# MSS_RCM_MSS_RCM register map
Vendor: Texas Instruments
Peripheral module from a debugger description file (folder AM263).
Registers are 8-bit, read-write, reset 0x0 unless marked. A register's access mark holds for its fields unless they carry their own. Offsets are as the file gives them; lines under a group give offsets from that group; [hi:lo] are bit positions; {n}, {i} and the like mark numbered series; 'fields as' and 'values as' point back to an identical list; <NAME> marks a mode.

## MSS_RCM_MSS_RCM
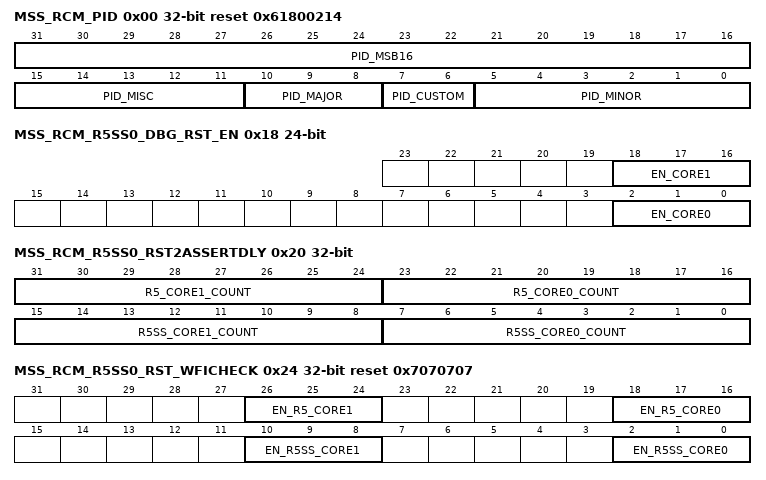
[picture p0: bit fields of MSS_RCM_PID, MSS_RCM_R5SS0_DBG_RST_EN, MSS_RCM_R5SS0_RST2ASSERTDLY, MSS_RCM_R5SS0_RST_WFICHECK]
0x00 MSS_RCM_PID 32-bit ro reset 0x61800214
  [31:16] PID_MSB16 — Not Defined
  [15:11] PID_MISC — Not Defined
  [10:8] PID_MAJOR — Not Defined
  [7:6] PID_CUSTOM — Not Defined
  [5:0] PID_MINOR — Not Defined
0x10 MSS_RCM_R5SS0_RST_STATUS 16-bit ro reset 0x3
  [10:0] CAUSE — Has the status because of which reset has happened. Bit0: POR ResetBit1: Warm Reset (ALso set during POR Reset)Bit2: CR5SS0 STC ResetBit3 Reset for CORE0 and MSS_CORE00_VIM using MSS_RCM::MSS_CR5SSA0_RST_CTRLBit4: Reset for CORE1 and MSS_CORE10_VIM using MSS_RCM::MSS_CR5SSB0_RST_CTRLBit5: Reset for CORE0 only using MSS_RCM::MSS_CORE00_RST_CTRLBit6: Reset for CORE1 only using using MSS_RCM::MSS_CORE10_RST_CTRLBit7: Reset for CORE0 and MSS_CORE00_VIM caused because of reset request by debugger in CORE00 Bit8: Reset for CORE10 and MSS_CORE10_VIM caused because of reset request by debugger in CORE10Bit9: Reset for CR5SS0 by the RESET FSM using MSS_CTRL::R5SS0_CONTROL_RESET_FSM_TRIGGER Bit 10 : MSS_RCM.MSS_CR5SS_POR_RST_CTRL0
0x14 MSS_RCM_R5SS0_RST_CAUSE_CLR
  [2:0] CLR — Write pulse bit field:Clear bit for rst cause register (writing '111' will clear the rst cause register)
0x18 MSS_RCM_R5SS0_DBG_RST_EN 24-bit
  [18:16] EN_CORE1 — writing '111' will block debug reset request from CORE1 toggling reset for CORE1 of respective R5SS
  [2:0] EN_CORE0 — writing '111' will block debug reset request from CORE0 toggling reset for CORE0 of respective R5SS
0x1C MSS_RCM_R5SS0_RST_ASSERDLY reset 0xF
  [7:0] COUNT — Value decides number of cycles reset should be kept asserted for CR5SS related resets. Programming a value of 0xFF will keep the reset asserted untill a new value other than 0xFF is written to this registerThe actual duration is count + 2 cycles. S/W Recommended value for this is 0x0FThe COUNT is applicable to both CPU cores
0x20 MSS_RCM_R5SS0_RST2ASSERTDLY 32-bit
  [31:24] R5_CORE1_COUNT — Value decides number of cycles to wait before asserting reset for local reset for CORE1
  [23:16] R5_CORE0_COUNT — Value decides number of cycles to wait before asserting reset for local reset for CORE0.
  [15:8] R5SS_CORE1_COUNT — Value decides number of cycles to wait before asserting reset for global reset for CORE1
  [7:0] R5SS_CORE0_COUNT — Value decides number of cycles to wait before asserting reset for global reset for CORE0.
0x24 MSS_RCM_R5SS0_RST_WFICHECK 32-bit reset 0x7070707
  [26:24] EN_R5_CORE1 — writing '000' will disable check for WFI before local reset assertion of CORE0
  [18:16] EN_R5_CORE0 — writing '000' will disable check for WFI before local reset assertion of CORE0
  [10:8] EN_R5SS_CORE1 — writing '000' will disable check for WFI before global reset assertion of CORE1
  [2:0] EN_R5SS_CORE0 — writing '000' will disable check for WFI before global reset assertion of CORE0
0x30 MSS_RCM_R5SS1_RST_STATUS 16-bit ro reset 0x3
  [10:0] CAUSE — Has the status because of which reset has happened. Bit0: POR ResetBit1: Warm Reset (ALso set during POR Reset)Bit2: CR5SS1 STC ResetBit3 Reset for CORE0 and MSS_CORE00_VIM using MSS_RCM::MSS_CR5SSA0_RST_CTRLBit4: Reset for CORE1 and MSS_CORE10_VIM using MSS_RCM::MSS_CR5SSB0_RST_CTRLBit5: Reset for CORE0 only using MSS_RCM::MSS_CORE00_RST_CTRLBit6: Reset for CORE1 only using using MSS_RCM::MSS_CORE10_RST_CTRLBit7: Reset for CORE0 and MSS_CORE00_VIM caused because of reset request by debugger in CORE00 Bit8: Reset for CORE10 and MSS_CORE10_VIM caused because of reset request by debugger in CORE10Bit9: Reset for CR5SS0 by the RESET FSM using MSS_CTRL::R5SS0_CONTROL_RESET_FSM_TRIGGER Bit 10 : MSS_RCM.MSS_CR5SS_POR_RST_CTRL0
0x34 MSS_RCM_R5SS1_RST_CAUSE_CLR
  fields as MSS_RCM_R5SS0_RST_CAUSE_CLR
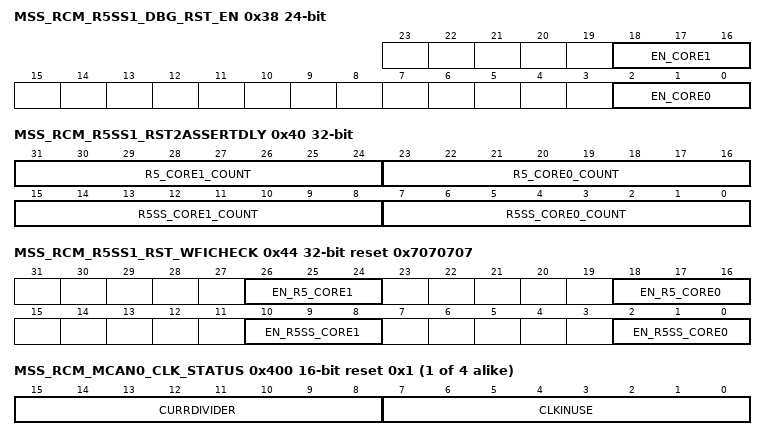
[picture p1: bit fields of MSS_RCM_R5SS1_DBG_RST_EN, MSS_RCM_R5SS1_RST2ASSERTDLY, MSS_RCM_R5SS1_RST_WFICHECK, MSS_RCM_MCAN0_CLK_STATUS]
0x38 MSS_RCM_R5SS1_DBG_RST_EN 24-bit
  fields as MSS_RCM_R5SS0_DBG_RST_EN
0x3C MSS_RCM_R5SS1_RST_ASSERDLY reset 0xF
  fields as MSS_RCM_R5SS0_RST_ASSERDLY
0x40 MSS_RCM_R5SS1_RST2ASSERTDLY 32-bit
  fields as MSS_RCM_R5SS0_RST2ASSERTDLY
0x44 MSS_RCM_R5SS1_RST_WFICHECK 32-bit reset 0x7070707
  fields as MSS_RCM_R5SS0_RST_WFICHECK
{0x100+4i} MSS_RCM_MCAN{i}_CLK_SRC_SEL 16-bit (i=0..3)
  [11:0] CLKSRCSEL — Select line for selecting source clock for corresponding MCAN.Data should be loaded as multibit. For example: if '0x5' should be selected then '0x555' should be configured to the register.Refer to AM602 clock spec for source clock reference
0x110 MSS_RCM_QSPI0_CLK_SRC_SEL 16-bit
  [11:0] CLKSRCSEL — Select line for selecting source clock for QSPI.Data should be loaded as multibit. For example: if '0x5' should be selected then '0x555' should be configured to the register.Refer to AM602 clock spec for source clock reference
{0x114+4i} MSS_RCM_RTI{i}_CLK_SRC_SEL 16-bit (i=0..3)
  [11:0] CLKSRCSEL — Select line for selecting source clock for Corresponding RTI.Data should be loaded as multibit. For example: if '0x5' should be selected then '0x555' should be configured to the register.Refer to AM602 clock spec for source clock reference
{0x128+4i} MSS_RCM_WDT{i}_CLK_SRC_SEL 16-bit (i=0..3)
  [11:0] CLKSRCSEL — Select line for selecting source clock for WDT.Data should be loaded as multibit. For example: if '0x5' should be selected then '0x555' should be configured to the register.Refer to AM602 clock spec for source clock reference
{0x13C+4i} MSS_RCM_MCSPI{i}_CLK_SRC_SEL 16-bit (i=0..4)
  [11:0] CLKSRCSEL — Select line for selecting source clock for Corresponding SPI.Data should be loaded as multibit. For example: if '0x5' should be selected then '0x555' should be configured to the register.Refer to AM602 clock spec for source clock reference
0x150 MSS_RCM_MMC0_CLK_SRC_SEL 16-bit
  [11:0] CLKSRCSEL — Select line for selecting source clock for MMCSD.Data should be loaded as multibit. For example: if '0x5' should be selected then '0x555' should be configured to the register.Refer to AM602 clock spec for source clock reference
0x154 MSS_RCM_ICSSM0_UART0_CLK_SRC_SEL 16-bit
  [11:0] CLKSRCSEL — Select line for selecting source clock for ICSSM_UCLK.Data should be loaded as multibit. For example: if '0x5' should be selected then '0x555' should be configured to the register.Refer to AM602 clock spec for source clock reference
0x158 MSS_RCM_CPTS_CLK_SRC_SEL 16-bit
  [11:0] CLKSRCSEL — Select line for selecting source clock for CPTS.Data should be loaded as multibit. For example: if '0x5' should be selected then '0x555' should be configured to the register.Refer to AM602 clock spec for source clock reference
0x15C MSS_RCM_GPMC_CLK_SRC_SEL 16-bit
  [11:0] GPMC_CLK_SRC_SEL — Select line for selecting source clock for GPMC. Data should be loaded as multibit. For example: if '0x5' should be selected then '0x555' should be configured to the register.Refer to AM602 clock spec for source clock reference
0x160 MSS_RCM_CONTROLSS_PLL_CLK_SRC_SEL 16-bit
  [11:0] CLKSRCSEL — Select line for selecting source clock for CONTROLSS_PLL.Data should be loaded as multibit. For example: if '0x5' should be selected then '0x555' should be configured to the register.Refer to AM602 clock spec for source clock reference
0x164 MSS_RCM_I2C_CLK_SRC_SEL 16-bit
  [11:0] CLKSRCSEL — Select line for selecting source clock for I2C.Data should be loaded as multibit. For example: if '0x5' should be selected then '0x555' should be configured to the register.Refer to AM602 clock spec for source clock reference
{0x174+4i} MSS_RCM_LIN{i}_UART{i}_CLK_SRC_SEL 16-bit (i=0..5)
  [11:0] CLKSRCSEL — Select line for selecting source clock for corresponding UART and LIN.Data should be loaded as multibit. For example: if '0x5' should be selected then '0x555' should be configured to the register.Refer to AM602 clock spec for source clock reference
{0x200+4i} MSS_RCM_MCAN{i}_CLK_DIV_VAL 16-bit (i=0..3)
  [11:0] CLKDIVR — Divider value corresponding MCAN selected clock.Data should be loaded as multibit. For example: if divider value of 8(1000) should be selected then '100010001000' should be configured to the register.Refer to AM602 clock planner for clock reference
0x210 MSS_RCM_QSPI0_CLK_DIV_VAL 16-bit
  [11:0] CLKDIVR — Divider value QSPI selected clock.Data should be loaded as multibit. For example: if divider value of '0x8' should be selected then '0x888' should be configured to the register.Refer to AM602 clock spec for clock reference
{0x214+4i} MSS_RCM_RTI{i}_CLK_DIV_VAL 16-bit (i=0..3)
  [11:0] CLKDIVR — Divider value Corresponding RTI selected clock.Data should be loaded as multibit. For example: if divider value of '0x8' should be selected then '0x888' should be configured to the register.Refer to AM602 clock spec for clock reference
{0x228+4i} MSS_RCM_WDT{i}_CLK_DIV_VAL 16-bit (i=0..3)
  [11:0] CLKDIVR — Divider value WDT selected clock.Data should be loaded as multibit. For example: if divider value of '0x8' should be selected then '0x888' should be configured to the register.Refer to AM602 clock spec for clock reference
{0x23C+4i} MSS_RCM_MCSPI{i}_CLK_DIV_VAL 16-bit (i=0..4)
  [11:0] CLKDIVR — Divider value Corresponding SPI selected clock.Data should be loaded as multibit. For example: if divider value of '0x8' should be selected then '0x888' should be configured to the register.Refer to AM602 clock spec for clock reference
0x250 MSS_RCM_MMC0_CLK_DIV_VAL 16-bit
  [11:0] CLKDIVR — Divider value MMCSD selected clock.Data should be loaded as multibit. For example: if divider value of '0x8' should be selected then '0x888' should be configured to the register.Refer to AM602 clock spec for clock reference
0x254 MSS_RCM_ICSSM0_UART_CLK_DIV_VAL 16-bit
  [11:0] CLKDIVR — Divider value ICSSM_UCLK selected clock.Data should be loaded as multibit. For example: if divider value of '0x8' should be selected then '0x888' should be configured to the register.Refer to AM602 clock spec for clock reference
0x258 MSS_RCM_CPTS_CLK_DIV_VAL 16-bit
  [11:0] CLKDIVR — Divider value CPTS selected clock.Data should be loaded as multibit. For example: if divider value of '0x8' should be selected then '0x888' should be configured to the register.Refer to AM602 clock spec for clock reference
0x25C MSS_RCM_GPMC_CLK_DIV_VAL 16-bit
  [11:0] CLKDIVR — Divider value GPMC selected clock.Data should be loaded as multibit. For example: if divider value of '0x8' should be selected then '0x888' should be configured to the register.Refer to AM602 clock spec for clock reference
0x260 MSS_RCM_CONTROLSS_PLL_CLK_DIV_VAL 16-bit
  [11:0] CLKDIVR — Divider value CONTROLSS_PLL selected clock.Data should be loaded as multibit. For example: if divider value of '0x8' should be selected then '0x888' should be configured to the register.Refer to AM602 clock spec for clock reference
0x264 MSS_RCM_I2C_CLK_DIV_VAL 16-bit
  [11:0] CLKDIVR — Divider value I2C selected clock.Data should be loaded as multibit. For example: if divider value of '0x8' should be selected then '0x888' should be configured to the register.Refer to AM602 clock spec for clock reference
{0x274+4i} MSS_RCM_LIN{i}_UART{i}_CLK_DIV_VAL 16-bit (i=0..5)
  [11:0] CLKDIVR — Divider value for corresponding UART and LIN selected clock.Data should be loaded as multibit. For example: if divider value of '0x8' should be selected then '0x888' should be configured to the register.Refer to AM602 clock spec for clock reference
0x28C MSS_RCM_RGMII_250_CLK_DIV_VAL 16-bit reset 0x111
  [11:0] CLKDIVR — Divider value RGMII selected clock.Data should be loaded as multibit. For example: if divider value of '0x8' should be selected then '0x888' should be configured to the register.Refer to AM602 clock spec for clock reference
0x290 MSS_RCM_RGMII_50_CLK_DIV_VAL 16-bit reset 0x999
  [11:0] CLKDIVR — Divider value MII100 selected clock.Data should be loaded as multibit. For example: if divider value of '0x8' should be selected then '0x888' should be configured to the register.Refer to AM602 clock spec for clock reference
0x294 MSS_RCM_RGMII_5_CLK_DIV_VAL 24-bit reset 0x636363
  [23:0] CLKDIVR — Divider value MII10 selected clock.Data should be loaded as multibit. For example: if divider value of '0x8' should be selected then '0x888' should be configured to the register.Refer to AM602 clock spec for clock reference
0x298 MSS_RCM_XTAL_MMC_32K_CLK_DIV_VAL 32-bit reset 0x30CC330C
  [29:0] CLKDIVR — Divider value for XTAL_32K clock.Data should be loaded as multibit. For example: if divider value of '0x30C' is required then '0x30CC330C' should be configured to the register.Refer to AM602 clock spec for clock reference
0x29C MSS_RCM_XTAL_TEMPSENSE_32K_CLK_DIV_VAL 32-bit reset 0x30CC330C
  fields as MSS_RCM_XTAL_MMC_32K_CLK_DIV_VAL
0x2A0 MSS_RCM_MSS_ELM_CLK_DIV_VAL 16-bit reset 0x333
  [11:0] CLKDIVR — Divider value ELM clock.Data should be loaded as multibit. For example: if divider value of '0x8' should be selected then '0x888' should be configured to the register.Refer to AM602 clock spec for clock reference
{0x300+4i} MSS_RCM_MCAN{i}_CLK_GATE (i=0..3)
  [2:0] GATED — writing '111' will gate clock for corresponding MCAN
0x310 MSS_RCM_QSPI0_CLK_GATE
  [2:0] GATED — writing '111' will gate clock for QSPI
{0x314+4i} MSS_RCM_RTI{i}_CLK_GATE (i=0..3)
  [2:0] GATED — writing '111' will gate clock for Corresponding RTI
{0x328+4i} MSS_RCM_WDT{i}_CLK_GATE (i=0..3)
  [2:0] GATED — writing '111' will gate clock for WDT
{0x33C+4i} MSS_RCM_MCSPI{i}_CLK_GATE (i=0..4)
  [2:0] GATED — writing '111' will gate clock for Corresponding SPI
0x350 MSS_RCM_MMC0_CLK_GATE
  [2:0] GATED — writing '111' will gate clock for MMCSD
0x354 MSS_RCM_ICSSM0_UART_CLK_GATE
  [2:0] GATED — writing '111' will gate clock for ICSSM_UCLK
0x358 MSS_RCM_CPTS_CLK_GATE
  [2:0] GATED — writing '111' will gate clock for CPTS
0x35C MSS_RCM_GPMC_CLK_GATE
  [2:0] GATED — writing '111' will gate clock for GPMC
0x360 MSS_RCM_CONTROLSS_PLL_CLK_GATE
  [2:0] GATED — writing '111' will gate clock for CONTROLSS_PLL
{0x364+4i} MSS_RCM_I2C{i}_CLK_GATE (i=0..3)
  [2:0] GATED — writing '111' will gate clock for I2C
{0x374+4i} MSS_RCM_LIN{i}_CLK_GATE (i=0..4)
  [2:0] GATED — writing '111' will gate clock for SPIB
{0x38C+4i} MSS_RCM_UART{i}_CLK_GATE (i=0..5)
  [2:0] GATED — writing '111' will gate clock for corresponding UART
0x3A4 MSS_RCM_RGMII_250_CLK_GATE
  [2:0] GATED — writing '111' will gate clock for RGMII
0x3A8 MSS_RCM_RGMII_50_CLK_GATE
  [2:0] GATED — writing '111' will gate clock for MII100
0x3AC MSS_RCM_RGMII_5_CLK_GATE
  [2:0] GATED — writing '111' will gate clock for MII10
0x3B0 MSS_RCM_MMC0_32K_CLK_GATE
  [2:0] GATED — writing '111' will gate clock for MMCSD_32K
0x3B4 MSS_RCM_TEMPSENSE_32K_CLK_GATE
  [2:0] GATED — writing '111' will gate clock for TEMPSENSE_32K
0x3B8 MSS_RCM_CPSW_CLK_GATE
  [2:0] GATED — writing '111' will gate clock for CPSW CPPI
0x3BC MSS_RCM_ICSSM0_IEP_CLK_GATE
  [2:0] GATED — writing '111' will gate clock for ICSSM_IEP
0x3C0 MSS_RCM_ICSSM0_CORE_CLK_GATE
  [2:0] GATED — writing '111' will gate clock for ICSSM_CORE
0x3C4 MSS_RCM_MSS_ICSSM_SYS_CLK_GATE
  [2:0] GATED — writing '111' will gate clock for ICSSM_SYS
0x3C8 MSS_RCM_MSS_ELM_CLK_GATE
  [2:0] GATED — writing '111' will gate clock for ELM
0x3CC MSS_RCM_R5SS0_CORE0_GATE
  [2:0] CLKGATE — writing '111' will gate clock to CORE0 related peripherals inside Cortexr5ss
0x3D0 MSS_RCM_R5SS1_CORE0_GATE
  fields as MSS_RCM_R5SS0_CORE0_GATE
0x3D4 MSS_RCM_R5SS0_CORE1_GATE
  [2:0] CLKGATE — writing '111' will gate clock to CORE1 related peripherals inside Cortexr5ss
0x3D8 MSS_RCM_R5SS1_CORE1_GATE
  fields as MSS_RCM_R5SS0_CORE1_GATE
{0x400+4i} MSS_RCM_MCAN{i}_CLK_STATUS 16-bit ro reset 0x1 (i=0..3)
  [15:8] CURRDIVIDER — Status shows the current divider value choosen for corresponding MCAN
  [7:0] CLKINUSE — Status shows the source clock slected for corresponding MCAN
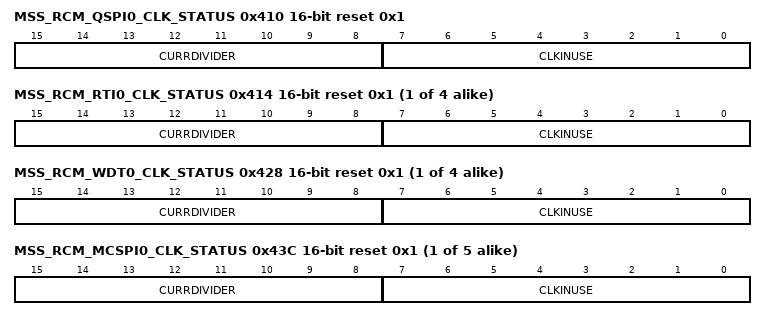
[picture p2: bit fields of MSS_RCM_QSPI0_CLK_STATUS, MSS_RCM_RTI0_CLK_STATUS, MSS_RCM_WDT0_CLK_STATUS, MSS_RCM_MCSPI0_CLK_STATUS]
0x410 MSS_RCM_QSPI0_CLK_STATUS 16-bit ro reset 0x1
  [15:8] CURRDIVIDER — Status shows the current divider value choosen for QSPI
  [7:0] CLKINUSE — Status shows the source clock slected for QSPI
{0x414+4i} MSS_RCM_RTI{i}_CLK_STATUS 16-bit ro reset 0x1 (i=0..3)
  [15:8] CURRDIVIDER — Status shows the current divider value choosen for Corresponding RTI
  [7:0] CLKINUSE — Status shows the source clock slected for Corresponding RTI
{0x428+4i} MSS_RCM_WDT{i}_CLK_STATUS 16-bit ro reset 0x1 (i=0..3)
  [15:8] CURRDIVIDER — Status shows the current divider value choosen for WDT
  [7:0] CLKINUSE — Status shows the source clock slected for WDT
{0x43C+4i} MSS_RCM_MCSPI{i}_CLK_STATUS 16-bit ro reset 0x1 (i=0..4)
  [15:8] CURRDIVIDER — Status shows the current divider value choosen for Corresponding SPI
  [7:0] CLKINUSE — Status shows the source clock slected for Corresponding SPI
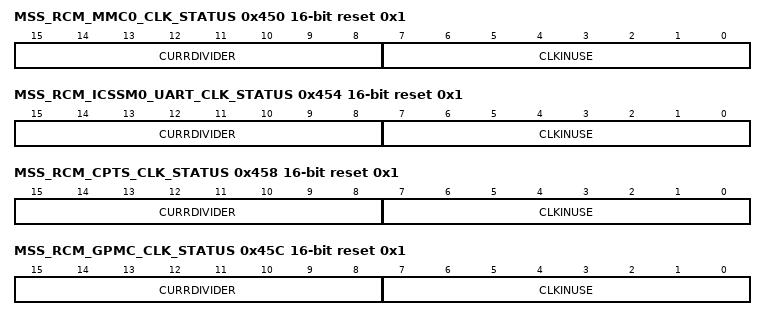
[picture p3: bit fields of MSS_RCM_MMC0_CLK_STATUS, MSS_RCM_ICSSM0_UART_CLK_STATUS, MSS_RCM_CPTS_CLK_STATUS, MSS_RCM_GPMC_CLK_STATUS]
0x450 MSS_RCM_MMC0_CLK_STATUS 16-bit ro reset 0x1
  [15:8] CURRDIVIDER — Status shows the current divider value choosen for MMCSD
  [7:0] CLKINUSE — Status shows the source clock slected for MMCSD
0x454 MSS_RCM_ICSSM0_UART_CLK_STATUS 16-bit ro reset 0x1
  [15:8] CURRDIVIDER — Status shows the current divider value choosen for ICSSM_UCLK
  [7:0] CLKINUSE — Status shows the source clock slected for ICSSM_UCLK
0x458 MSS_RCM_CPTS_CLK_STATUS 16-bit ro reset 0x1
  [15:8] CURRDIVIDER — Status shows the current divider value choosen for CPTS
  [7:0] CLKINUSE — Status shows the source clock slected for CPTS
0x45C MSS_RCM_GPMC_CLK_STATUS 16-bit ro reset 0x1
  [15:8] CURRDIVIDER — Status shows the current divider value choosen for GPMC
  [7:0] CLKINUSE — Status shows the source clock slected for GPMC
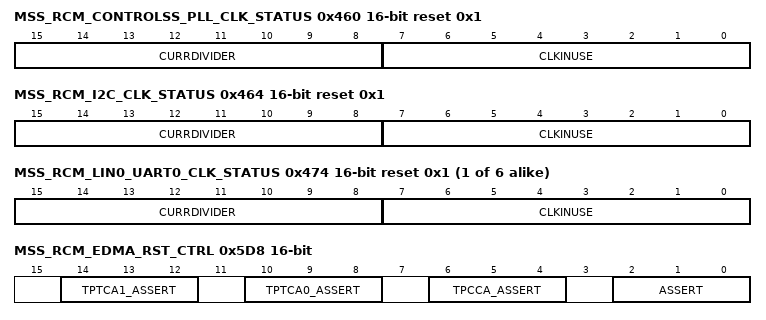
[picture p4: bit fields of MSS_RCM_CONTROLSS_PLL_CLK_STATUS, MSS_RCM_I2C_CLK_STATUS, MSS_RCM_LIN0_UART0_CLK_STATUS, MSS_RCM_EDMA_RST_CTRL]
0x460 MSS_RCM_CONTROLSS_PLL_CLK_STATUS 16-bit ro reset 0x1
  [15:8] CURRDIVIDER — Status shows the current divider value choosen for CONTROLSS_PLL
  [7:0] CLKINUSE — Status shows the source clock slected for CONTROLSS_PLL
0x464 MSS_RCM_I2C_CLK_STATUS 16-bit ro reset 0x1
  [15:8] CURRDIVIDER — Status shows the current divider value choosen for I2C
  [7:0] CLKINUSE — Status shows the source clock slected for I2C
{0x474+4i} MSS_RCM_LIN{i}_UART{i}_CLK_STATUS 16-bit ro reset 0x1 (i=0..5)
  [15:8] CURRDIVIDER — Status shows the current divider value choosen for corresponding UART and LIN
  [7:0] CLKINUSE — Status shows the source clock slected for corresponding UART and LIN
0x48C MSS_RCM_RGMII_250_CLK_STATUS 16-bit ro reset 0x100
  [15:8] CURRDIVIDER — Status shows the current divider value choosen for RGMII
0x490 MSS_RCM_RGMII_50_CLK_STATUS 16-bit ro reset 0x900
  [15:8] CURRDIVIDER — Status shows the current divider value choosen for MII100
0x494 MSS_RCM_RGMII_5_CLK_STATUS 16-bit ro reset 0x6300
  [15:8] CURRDIVIDER — Status shows the current divider value choosen for MII10
0x49C MSS_RCM_MMC0_32K_CLK_STATUS 24-bit ro reset 0x30C00
  [17:8] CURRDIVIDER — Status shows the current divider value choosen for XTAL_32K
0x4A0 MSS_RCM_TEMPSENSE_32K_CLK_STATUS 24-bit ro reset 0x30C00
  fields as MSS_RCM_MMC0_32K_CLK_STATUS
0x4A4 MSS_RCM_MSS_ELM_CLK_STATUS 16-bit ro reset 0x300
  [15:8] CURRDIVIDER — Status shows the current divider value choosen for ELM
0x500 MSS_RCM_R5SS0_POR_RST_CTRL
  [2:0] ASSERT — This feature is for debug purpose only. Software needs to ensure the state of the Device/IP before configuring.write pulse bit field:writing '111' will assert por reset to R5SS Read is always 000
0x504 MSS_RCM_R5SS1_POR_RST_CTRL
  fields as MSS_RCM_R5SS0_POR_RST_CTRL
0x508 MSS_RCM_R5SS0_CORE0_GRST_CTRL
  [2:0] ASSERT — This feature is for debug purpose only. Software needs to ensure the state of the Device/IP before configuring.write pulse bit field:writing '111' will reset CORE0 and MSS_CORE0_VIM
0x50C MSS_RCM_R5SS1_CORE0_GRST_CTRL
  fields as MSS_RCM_R5SS0_CORE0_GRST_CTRL
0x510 MSS_RCM_R5SS0_CORE1_GRST_CTRL
  [2:0] ASSERT — This feature is for debug purpose only. Software needs to ensure the state of the Device/IP before configuring.write pulse bit field:writing '111' will reset CORE1 and MSS_CORE1_VIM
0x514 MSS_RCM_R5SS1_CORE1_GRST_CTRL
  fields as MSS_RCM_R5SS0_CORE1_GRST_CTRL
0x518 MSS_RCM_R5SS0_CORE0_LRST_CTRL
  [2:0] ASSERT — This feature is for debug purpose only. Software needs to ensure the state of the Device/IP before configuring.write pulse bit field:writing '111' will reset CORE0 only
0x51C MSS_RCM_R5SS1_CORE0_LRST_CTRL
  fields as MSS_RCM_R5SS0_CORE0_LRST_CTRL
0x520 MSS_RCM_R5SS0_CORE1_LRST_CTRL
  [2:0] ASSERT — This feature is for debug purpose only. Software needs to ensure the state of the Device/IP before configuring.write pulse bit field:writing '111' will reset CORE1 only
0x524 MSS_RCM_R5SS1_CORE1_LRST_CTRL
  fields as MSS_RCM_R5SS0_CORE1_LRST_CTRL
0x528 MSS_RCM_R5SS0_VIM0_RST_CTRL
  [2:0] ASSERT — This feature is for debug purpose only. Software needs to ensure the state of the Device/IP before configuring. Writing '111' will reset MSS_CORE0_VIM Writing 000 will deassert the reset
0x52C MSS_RCM_R5SS1_VIM0_RST_CTRL
  fields as MSS_RCM_R5SS0_VIM0_RST_CTRL
0x530 MSS_RCM_R5SS0_VIM1_RST_CTRL
  [2:0] ASSERT — This feature is for debug purpose only. Software needs to ensure the state of the Device/IP before configuring. Writing '111' will reset MSS_CORE1_VIM
0x534 MSS_RCM_R5SS1_VIM1_RST_CTRL
  fields as MSS_RCM_R5SS0_VIM1_RST_CTRL
0x538 MSS_RCM_MCRC0_RST_CTRL
  [2:0] ASSERT — This feature is for debug purpose only. Software needs to ensure the state of the Device/IP before configuring. Writing '111' will reset MCRC
{0x53C+4i} MSS_RCM_RTI{i}_RST_CTRL (i=0..3)
  [2:0] ASSERT — This feature is for debug purpose only. Software needs to ensure the state of the Device/IP before configuring. Writing '111' will reset corresponding RTI
{0x54C+4i} MSS_RCM_WDT{i}_RST_CTRL (i=0..3)
  [2:0] ASSERT — This feature is for debug purpose only. Software needs to ensure the state of the Device/IP before configuring. Writing '111' will reset WDT
0x55C MSS_RCM_TOP_ESM_RST_CTRL
  [2:0] ASSERT — This feature is for debug purpose only. Software needs to ensure the state of the Device/IP before configuring. Writing '111' will reset ESM
0x560 MSS_RCM_DCC0_RST_CTRL
  [2:0] ASSERT — This feature is for debug purpose only. Software needs to ensure the state of the Device/IP before configuring. Writing '111' will reset DCCA
0x564 MSS_RCM_DCC1_RST_CTRL
  [2:0] ASSERT — This feature is for debug purpose only. Software needs to ensure the state of the Device/IP before configuring. Writing '111' will reset DCCB
0x568 MSS_RCM_DCC2_RST_CTRL
  [2:0] ASSERT — This feature is for debug purpose only. Software needs to ensure the state of the Device/IP before configuring. Writing '111' will reset DCCC
0x56C MSS_RCM_DCC3_RST_CTRL
  [2:0] ASSERT — This feature is for debug purpose only. Software needs to ensure the state of the Device/IP before configuring. Writing '111' will reset DCCD
{0x570+4i} MSS_RCM_MCSPI{i}_RST_CTRL (i=0..4)
  [2:0] ASSERT — This feature is for debug purpose only. Software needs to ensure the state of the Device/IP before configuring. Writing '111' will reset Corresponding SPI
0x584 MSS_RCM_QSPI0_RST_CTRL
  [2:0] ASSERT — This feature is for debug purpose only. Software needs to ensure the state of the Device/IP before configuring. Writing '111' will reset QSPI
{0x588+4i} MSS_RCM_MCAN{i}_RST_CTRL (i=0..3)
  [2:0] ASSERT — This feature is for debug purpose only. Software needs to ensure the state of the Device/IP before configuring. Writing '111' will reset corresponding MCAN
{0x598+4i} MSS_RCM_I2C{i}_RST_CTRL (i=0..3)
  [2:0] ASSERT — This feature is for debug purpose only. Software needs to ensure the state of the Device/IP before configuring. Writing '111' will reset corresponding I2C
{0x5A8+4i} MSS_RCM_UART{i}_RST_CTRL (i=0..5)
  [2:0] ASSERT — This feature is for debug purpose only. Software needs to ensure the state of the Device/IP before configuring. Writing '111' will reset corresponding UART instance
{0x5C0+4i} MSS_RCM_LIN{i}_RST_CTRL (i=0..4)
  [2:0] ASSERT — This feature is for debug purpose only. Software needs to ensure the state of the Device/IP before configuring. Writing '111' will reset LIN
0x5D8 MSS_RCM_EDMA_RST_CTRL 16-bit
  [14:12] TPTCA1_ASSERT — This feature is for debug purpose only. Software needs to ensure the state of the Device/IP before configuring. Writing '111' will reset MSS_TPTCA1
  [10:8] TPTCA0_ASSERT — This feature is for debug purpose only. Software needs to ensure the state of the Device/IP before configuring. Writing '111' will reset MSS_TPTCA0
  [6:4] TPCCA_ASSERT — This feature is for debug purpose only. Software needs to ensure the state of the Device/IP before configuring. Writing '111' will reset MSS_TPCCA
  [2:0] ASSERT — This feature is for debug purpose only. Software needs to ensure the state of the Device/IP before configuring. Writing '111' will reset EDMA
0x5DC MSS_RCM_INFRA_RST_CTRL
  [2:0] ASSERT — This feature is for debug purpose only. Software needs to ensure the state of the Device/IP before configuring. Writing '111' will reset MSS INFRA
0x5E0 MSS_RCM_CPSW_RST_CTRL
  [2:0] ASSERT — This feature is for debug purpose only. Software needs to ensure the state of the Device/IP before configuring. Writing '111' will reset MSS CPSW
0x5E4 MSS_RCM_ICSSM0_RST_CTRL
  [2:0] ASSERT — This feature is for debug purpose only. Software needs to ensure the state of the Device/IP before configuring. Writing '111' will reset MSS ICSSM
0x5E8 MSS_RCM_MMC0_RST_CTRL
  [2:0] ASSERT — This feature is for debug purpose only. Software needs to ensure the state of the Device/IP before configuring. Writing '111' will reset MMCSD
{0x5EC+4i} MSS_RCM_GPIO{i}_RST_CTRL (i=0..3)
  [2:0] ASSERT — This feature is for debug purpose only. Software needs to ensure the state of the Device/IP before configuring. Writing '111' will reset corresponding GPIO
0x5FC MSS_RCM_SPINLOCK0_RST_CTRL
  [2:0] ASSERT — This feature is for debug purpose only. Software needs to ensure the state of the Device/IP before configuring. Writing '111' will reset SPINLOCK
0x600 MSS_RCM_GPMC_RST_CTRL
  [2:0] ASSERT — This feature is for debug purpose only. Software needs to ensure the state of the Device/IP before configuring. Writing '111' will reset GPMC
0x604 MSS_RCM_TEMPSENSE_32K_RST_CTRL
  [2:0] ASSERT — This feature is for debug purpose only. Software needs to ensure the state of the Device/IP before configuring. Writing '111' will reset TEMPSENSE
0x608 MSS_RCM_MSS_ELM_RST_CTRL
  [2:0] ASSERT — This feature is for debug purpose only. Software needs to ensure the state of the Device/IP before configuring. Writing '111' will reset ELM
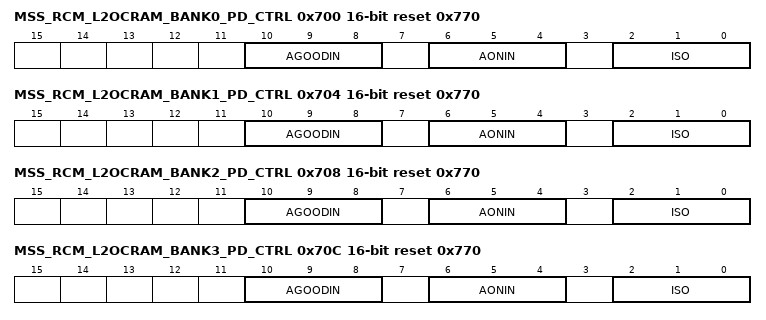
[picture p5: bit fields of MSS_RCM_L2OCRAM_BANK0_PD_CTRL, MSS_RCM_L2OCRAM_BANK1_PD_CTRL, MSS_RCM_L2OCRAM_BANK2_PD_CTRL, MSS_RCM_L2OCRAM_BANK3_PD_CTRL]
0x700 MSS_RCM_L2OCRAM_BANK0_PD_CTRL 16-bit reset 0x770
  [10:8] AGOODIN — SW control for power signal 'AGOODIN' for MSS_L2_BANKA
  [6:4] AONIN — SW control for power signal 'AONIN' for MSS_L2_BANKA
  [2:0] ISO — SW control for power signal 'ISO' for MSS_L2_BANKA
0x704 MSS_RCM_L2OCRAM_BANK1_PD_CTRL 16-bit reset 0x770
  [10:8] AGOODIN — SW control for power signal 'AGOODIN' for MSS_L2_BANKB
  [6:4] AONIN — SW control for power signal 'AONIN' for MSS_L2_BANKB
  [2:0] ISO — SW control for power signal 'ISO' for MSS_L2_BANKB
0x708 MSS_RCM_L2OCRAM_BANK2_PD_CTRL 16-bit reset 0x770
  [10:8] AGOODIN — SW control for power signal 'AGOODIN' for MSS_L2_BANKC
  [6:4] AONIN — SW control for power signal 'AONIN' for MSS_L2_BANKC
  [2:0] ISO — SW control for power signal 'ISO' for MSS_L2_BANKC
0x70C MSS_RCM_L2OCRAM_BANK3_PD_CTRL 16-bit reset 0x770
  [10:8] AGOODIN — SW control for power signal 'AGOODIN' for MSS_L2_BANKD
  [6:4] AONIN — SW control for power signal 'AONIN' for MSS_L2_BANKD
  [2:0] ISO — SW control for power signal 'ISO' for MSS_L2_BANKD
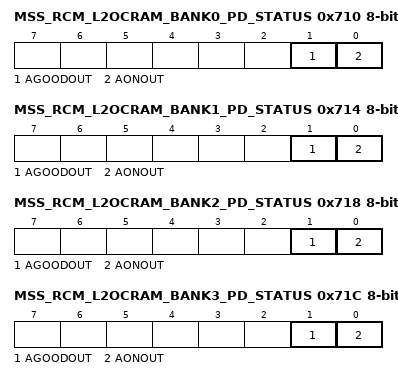
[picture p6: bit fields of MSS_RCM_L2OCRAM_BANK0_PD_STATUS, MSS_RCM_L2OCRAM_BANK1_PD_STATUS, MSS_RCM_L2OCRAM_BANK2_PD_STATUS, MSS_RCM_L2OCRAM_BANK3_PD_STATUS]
0x710 MSS_RCM_L2OCRAM_BANK0_PD_STATUS ro reset 0x3
  [1] AGOODOUT — SW status indicating the 'pgoodin' of MSS_L2_BANKA
  [0] AONOUT — SW status indicating the 'ponin' of MSS_L2_BANKA
0x714 MSS_RCM_L2OCRAM_BANK1_PD_STATUS ro reset 0x3
  [1] AGOODOUT — SW status indicating the 'pgoodin' of MSS_L2_BANKB
  [0] AONOUT — SW status indicating the 'ponin' of MSS_L2_BANKB
0x718 MSS_RCM_L2OCRAM_BANK2_PD_STATUS ro reset 0x3
  [1] AGOODOUT — SW status indicating the 'pgoodin' of MSS_L2_BANKC
  [0] AONOUT — SW status indicating the 'ponin' of MSS_L2_BANKC
0x71C MSS_RCM_L2OCRAM_BANK3_PD_STATUS ro reset 0x3
  [1] AGOODOUT — SW status indicating the 'pgoodin' of MSS_L2_BANKD
  [0] AONOUT — SW status indicating the 'ponin' of MSS_L2_BANKD
{0x720+4i} MSS_RCM_HW_REG{i} 32-bit (i=0..3)
  [31:0] HWREG — HW Reserved regiser
0x800 MSS_RCM_HSM_RTIA_CLK_SRC_SEL 16-bit
  [11:0] HSM_RTI0_CLK_SRC_SEL — Select line for selecting source clock for HSM_Corresponding RTI.Data should be loaded as multibit. For example: if '0x5' should be selected then '0x555' should be configured to the register.Refer to AM602 clock spec for source clock reference
0x804 MSS_RCM_HSM_WDT_CLK_SRC_SEL 16-bit
  [11:0] HSM_WDT0_CLK_SRC_SEL — Select line for selecting source clock for HSM_WDT.Data should be loaded as multibit. For example: if '0x5' should be selected then '0x555' should be configured to the register.Refer to AM602 clock spec for source clock reference
0x808 MSS_RCM_HSM_RTC_CLK_SRC_SEL 16-bit reset 0x777
  [11:0] HSM_RTC0_CLK_SRC_SEL — Select line for selecting source clock for HSM_RTC.Data should be loaded as multibit. For example: if '0x5' should be selected then '0x555' should be configured to the register.Refer to AM602 clock spec for source clock reference
0x80C MSS_RCM_HSM_DMTA_CLK_SRC_SEL 16-bit
  [11:0] HSM_DTM0_CLK_SRC_SEL — Select line for selecting source clock for HSM_DMTA.Data should be loaded as multibit. For example: if '0x5' should be selected then '0x555' should be configured to the register.Refer to AM602 clock spec for source clock reference
0x810 MSS_RCM_HSM_DMTB_CLK_SRC_SEL 16-bit
  [11:0] HSM_DTM1_CLK_SRC_SEL — Select line for selecting source clock for HSM_DMTB.Data should be loaded as multibit. For example: if '0x5' should be selected then '0x555' should be configured to the register.Refer to AM602 clock spec for source clock reference
0x814 MSS_RCM_HSM_RTI_CLK_DIV_VAL 16-bit
  [11:0] CLKDIVR — Divider value HSM RTI selected clock.Data should be loaded as multibit. For example: if divider value of '0x8' should be selected then '0x888' should be configured to the register.Refer to AM602 clock spec for clock reference
0x818 MSS_RCM_HSM_WDT_CLK_DIV_VAL 16-bit
  [11:0] CLKDIVR — Divider value HSM WDT selected clock.Data should be loaded as multibit. For example: if divider value of '0x8' should be selected then '0x888' should be configured to the register.Refer to AM602 clock spec for clock reference
0x81C MSS_RCM_HSM_RTC_CLK_DIV_VAL 16-bit
  [11:0] CLKDIVR — Divider value HSM RTC selected clock.Data should be loaded as multibit. For example: if divider value of '0x8' should be selected then '0x888' should be configured to the register.Refer to AM602 clock spec for clock reference
0x820 MSS_RCM_HSM_DMTA_CLK_DIV_VAL 16-bit
  [11:0] CLKDIVR — Divider value HSM DMTA selected clock.Data should be loaded as multibit. For example: if divider value of '0x8' should be selected then '0x888' should be configured to the register.Refer to AM602 clock spec for clock reference
0x824 MSS_RCM_HSM_DMTB_CLK_DIV_VAL 16-bit
  [11:0] CLKDIVR — Divider value HSM DMTB selected clock.Data should be loaded as multibit. For example: if divider value of '0x8' should be selected then '0x888' should be configured to the register.Refer to AM602 clock spec for clock reference
0x828 MSS_RCM_HSM_RTI_CLK_GATE
  [2:0] GATED — writing '111' will gate clock for HSM RTI
0x82C MSS_RCM_HSM_WDT_CLK_GATE
  [2:0] GATED — writing '111' will gate clock for HSM WDT
0x830 MSS_RCM_HSM_RTC_CLK_GATE
  [2:0] GATED — writing '111' will gate clock for HSM RTC
0x834 MSS_RCM_HSM_DMTA_CLK_GATE
  [2:0] GATED — writing '111' will gate clock for HSM DMTA
0x838 MSS_RCM_HSM_DMTB_CLK_GATE
  [2:0] GATED — writing '111' will gate clock for HSM DMTB
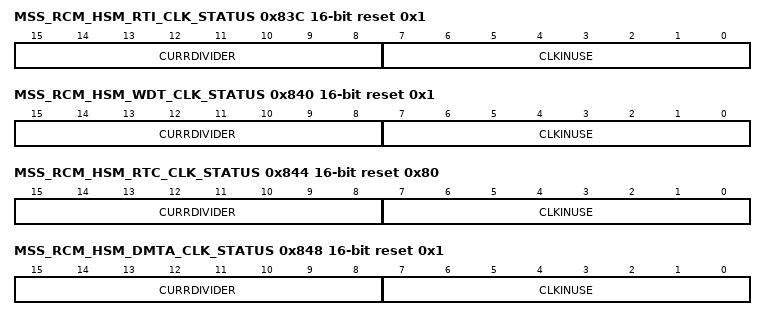
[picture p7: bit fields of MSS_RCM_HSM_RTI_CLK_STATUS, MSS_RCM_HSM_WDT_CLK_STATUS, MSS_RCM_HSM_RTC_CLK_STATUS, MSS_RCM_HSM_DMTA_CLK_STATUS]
0x83C MSS_RCM_HSM_RTI_CLK_STATUS 16-bit ro reset 0x1
  [15:8] CURRDIVIDER — Status shows the current divider value choosen for HSM_RTI
  [7:0] CLKINUSE — Status shows the source clock slected for HSM_RTI
0x840 MSS_RCM_HSM_WDT_CLK_STATUS 16-bit ro reset 0x1
  [15:8] CURRDIVIDER — Status shows the current divider value choosen for HSM_WDT
  [7:0] CLKINUSE — Status shows the source clock slected for HSM_WDT
0x844 MSS_RCM_HSM_RTC_CLK_STATUS 16-bit ro reset 0x80
  [15:8] CURRDIVIDER — Status shows the current divider value choosen for HSM_RTC
  [7:0] CLKINUSE — Status shows the source clock slected for HSM_RTC
0x848 MSS_RCM_HSM_DMTA_CLK_STATUS 16-bit ro reset 0x1
  [15:8] CURRDIVIDER — Status shows the current divider value choosen for HSM_DMTA
  [7:0] CLKINUSE — Status shows the source clock slected for HSM_DMTA
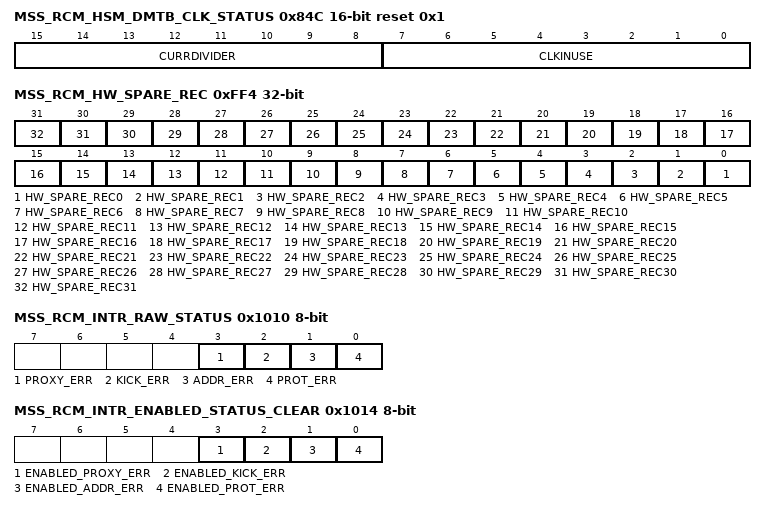
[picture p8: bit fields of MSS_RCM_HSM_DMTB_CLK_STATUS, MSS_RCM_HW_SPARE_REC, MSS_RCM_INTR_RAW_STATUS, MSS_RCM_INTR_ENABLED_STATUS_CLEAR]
0x84C MSS_RCM_HSM_DMTB_CLK_STATUS 16-bit ro reset 0x1
  [15:8] CURRDIVIDER — Status shows the current divider value choosen for HSM_DMTB
  [7:0] CLKINUSE — Status shows the source clock slected for HSM_DMTB
{0xFD0+4i} MSS_RCM_HW_SPARE_RW{i} 32-bit (i=0..3)
  [31:0] HW_SPARE_RW{i} — Reserved for HW R&D
{0xFE0+4i} MSS_RCM_HW_SPARE_RO{i} 32-bit ro (i=0..3)
  [31:0] HW_SPARE_RO{i} — Reserved for HW R&D
0xFF0 MSS_RCM_HW_SPARE_WPH 32-bit
  [31:0] HW_SPARE_WPH — Reserved for HW R&D
0xFF4 MSS_RCM_HW_SPARE_REC 32-bit
  [n] HW_SPARE_REC{n} (n=0..31) — Reserved for HW R&D
0x1008 MSS_RCM_LOCK0_KICK0 32-bit
  [31:0] LOCK0_KICK0 — - KICK0 component
0x100C MSS_RCM_LOCK0_KICK1 32-bit
  [31:0] LOCK0_KICK1 — - KICK1 component
0x1010 MSS_RCM_INTR_RAW_STATUS
  [3] PROXY_ERR — Proxy0 access violation error. Raw status is read. Write a 1 to set the status. Writing a 0 has no effect.
  [2] KICK_ERR — Kick access violation error. Raw status is read. Write a 1 to set the status. Writing a 0 has no effect.
  [1] ADDR_ERR — Addressing violation error. Raw status is read. Write a 1 to set the status. Writing a 0 has no effect.
  [0] PROT_ERR — Protection violation error. Raw status is read. Write a 1 to set the status. Writing a 0 has no effect.
0x1014 MSS_RCM_INTR_ENABLED_STATUS_CLEAR
  [3] ENABLED_PROXY_ERR — Proxy0 access violation error. Enabled status is read. Write a 1 to clear the status. Writing a 0 has no effect.
  [2] ENABLED_KICK_ERR — Kick access violation error. Enabled status is read. Write a 1 to clear the status. Writing a 0 has no effect.
  [1] ENABLED_ADDR_ERR — Addressing violation error. Enabled status is read. Write a 1 to clear the status. Writing a 0 has no effect.
  [0] ENABLED_PROT_ERR — Protection violation error. Enabled status is read. Write a 1 to clear the status. Writing a 0 has no effect.
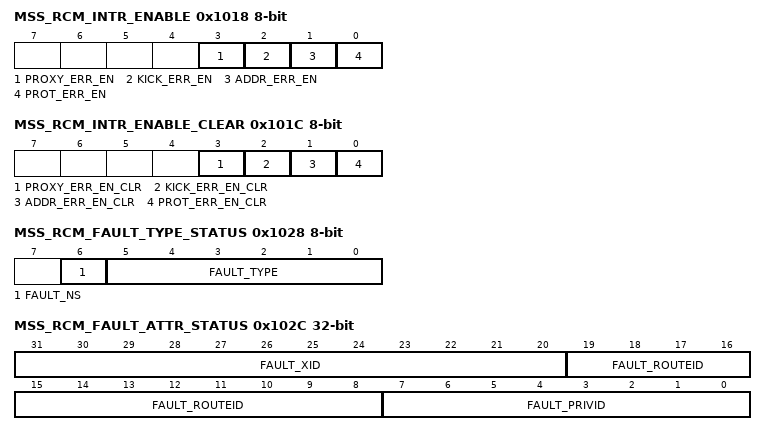
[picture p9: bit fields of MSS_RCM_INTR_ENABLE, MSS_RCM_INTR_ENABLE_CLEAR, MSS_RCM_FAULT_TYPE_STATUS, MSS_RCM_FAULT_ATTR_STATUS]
0x1018 MSS_RCM_INTR_ENABLE
  [3] PROXY_ERR_EN — Proxy0 access violation error enable. Write a 1 to set the enable. Writing a 0 has no effect.
  [2] KICK_ERR_EN — Kick access violation error enable. Write a 1 to set the enable. Writing a 0 has no effect.
  [1] ADDR_ERR_EN — Addressing violation error enable. Write a 1 to set the enable. Writing a 0 has no effect.
  [0] PROT_ERR_EN — Protection violation error enable. Write a 1 to set the enable. Writing a 0 has no effect.
0x101C MSS_RCM_INTR_ENABLE_CLEAR
  [3] PROXY_ERR_EN_CLR — Proxy0 access violation error enable clear. Write a 1 to clear the enable. Writing a 0 has no effect.
  [2] KICK_ERR_EN_CLR — Kick access violation error enable clear. Write a 1 to clear the enable. Writing a 0 has no effect.
  [1] ADDR_ERR_EN_CLR — Addressing violation error enable clear. Write a 1 to clear the enable. Writing a 0 has no effect.
  [0] PROT_ERR_EN_CLR — Protection violation error enable clear. Write a 1 to clear the enable. Writing a 0 has no effect.
0x1020 MSS_RCM_EOI
  [7:0] EOI_VECTOR — EOI vector value. Write this with interrupt distribution value in the chip.
0x1024 MSS_RCM_FAULT_ADDRESS 32-bit ro
  [31:0] FAULT_ADDR — Fault Address.
0x1028 MSS_RCM_FAULT_TYPE_STATUS ro
  [6] FAULT_NS — Non-secure access.
  [5:0] FAULT_TYPE — Fault Type 10_0000 = Supervisor read fault - priv = 1 dir = 1 dtype != 1 01_0000 = Supervisor write fault - priv = 1 dir = 0 00_1000 = Supervisor execute fault - priv = 1 dir = 1 dtype = 1 00_0100 = User read fault - priv = 0 dir = 1 dtype = 1 00_0010 = User write fault - priv = 0 dir = 0 00_0001 = User execute fault - priv = 0 dir = 1 dtype = 1 00_0000 = No fault
0x102C MSS_RCM_FAULT_ATTR_STATUS 32-bit ro
  [31:20] FAULT_XID — XID.
  [19:8] FAULT_ROUTEID — Route ID.
  [7:0] FAULT_PRIVID — Privilege ID.
0x1030 MSS_RCM_FAULT_CLEAR size not given wo
  [0] FAULT_CLR — Fault clear. Writing a 1 clears the current fault. Writing a 0 has no effect.
